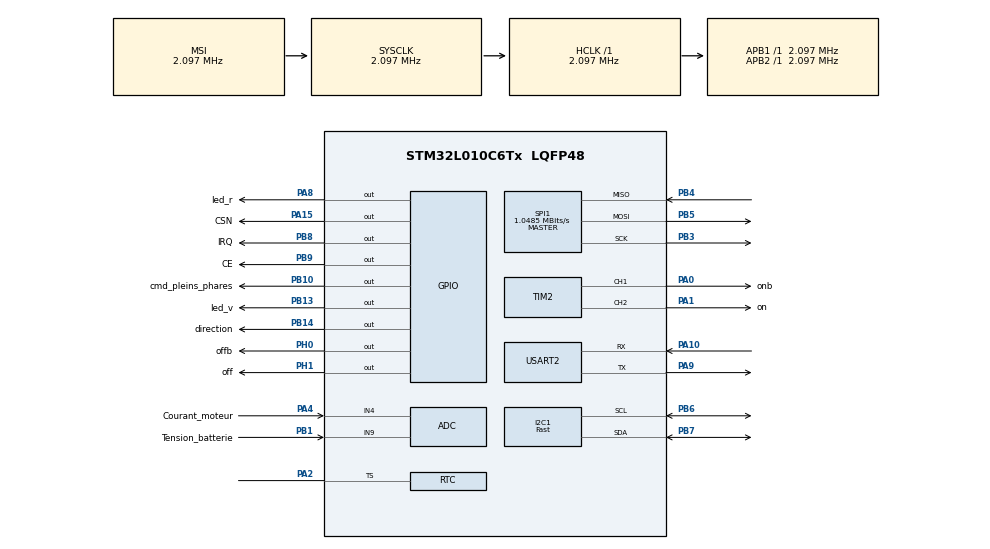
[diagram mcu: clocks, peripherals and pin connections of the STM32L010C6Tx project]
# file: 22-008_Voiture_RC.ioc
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I2C1.I2C_Speed_Mode=I2C_Fast
I2C1.Timing=0x00000000
Mcu.Family=STM32L0
Mcu.Name=STM32L010C6Tx
Mcu.Package=LQFP48
PA0.GPIO_Label=onb
PA0.GPIO_PuPd=GPIO_PULLDOWN
PA0.Signal=S_TIM2_CH1
PA1.GPIO_Label=on
PA1.GPIO_PuPd=GPIO_PULLDOWN
PA1.Signal=S_TIM2_CH2
PA10.Mode=Asynchronous
PA10.Signal=USART2_RX
PA15.GPIO_Label=CSN
PA15.Signal=GPIO_Output
PA2.Mode=Timestamp enabled
PA2.Signal=RTC_TS
PA4.GPIO_Label=Courant_moteur
PA4.Mode=IN4
PA4.Signal=ADC_IN4
PA8.GPIO_Label=led_r
PA8.PinState=GPIO_PIN_SET
PA8.Signal=GPIO_Output
PA9.Mode=Asynchronous
PA9.Signal=USART2_TX
PB1.GPIO_Label=Tension_batterie
PB1.Mode=IN9
PB1.Signal=ADC_IN9
PB10.GPIO_Label=cmd_pleins_phares
PB10.Signal=GPIO_Output
PB13.GPIO_Label=led_v
PB13.PinState=GPIO_PIN_SET
PB13.Signal=GPIO_Output
PB14.GPIO_Label=direction
PB14.Signal=GPIO_Output
PB3.Mode=Full_Duplex_Master
PB3.Signal=SPI1_SCK
PB4.Mode=Full_Duplex_Master
PB4.Signal=SPI1_MISO
PB5.Mode=Full_Duplex_Master
PB5.Signal=SPI1_MOSI
PB6.Mode=I2C
PB6.Signal=I2C1_SCL
PB7.Mode=I2C
PB7.Signal=I2C1_SDA
PB8.GPIO_Label=IRQ
PB8.Signal=GPIO_Output
PB9.GPIO_Label=CE
PB9.Signal=GPIO_Output
PH0-OSC_IN.GPIO_Label=offb
PH0-OSC_IN.GPIO_PuPd=GPIO_PULLDOWN
PH0-OSC_IN.Signal=GPIO_Output
PH1-OSC_OUT.GPIO_Label=off
PH1-OSC_OUT.GPIO_PuPd=GPIO_PULLDOWN
PH1-OSC_OUT.Signal=GPIO_Output
ProjectManager.HeapSize=0x200
ProjectManager.StackSize=0x400
ProjectManager.TargetToolchain=STM32CubeIDE
RCC.AHBFreq_Value=2097000
RCC.APB1Freq_Value=2097000
RCC.APB1TimFreq_Value=2097000
RCC.APB2Freq_Value=2097000
RCC.APB2TimFreq_Value=2097000
RCC.HCLKFreq_Value=2097000
RCC.HSE_VALUE=8000000
RCC.HSI16_VALUE=16000000
RCC.HSI_VALUE=16000000
RCC.LSE_VALUE=32768
RCC.MSI_VALUE=2097000
RCC.SYSCLKFreq_VALUE=2097000
RCC.VCOOutputFreq_Value=48000000
RTC.Year=70
SH.S_TIM2_CH1.0=TIM2_CH1,PWM Generation1 CH1
SH.S_TIM2_CH2.0=TIM2_CH2,PWM Generation2 CH2
SPI1.CalculateBaudRate=1.0485 MBits/s
SPI1.Direction=SPI_DIRECTION_2LINES
SPI1.Mode=SPI_MODE_MASTER
SPI1.VirtualType=VM_MASTER
TIM2.Channel-PWM\ Generation1\ CH1=TIM_CHANNEL_1
TIM2.Channel-PWM\ Generation2\ CH2=TIM_CHANNEL_2
USART2.VirtualMode=VM_ASYNC
VP_RTC_VS_RTC_Activate.Mode=RTC_Enabled
VP_RTC_VS_RTC_Calendar.Mode=RTC_Calendar
VP_TIM2_VS_ClockSourceINT.Mode=Internal
board=custom

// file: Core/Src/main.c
/* USER CODE BEGIN Header */
/**
  ******************************************************************************
  * @file           : main.c
  * @brief          : Main program body
  ******************************************************************************
  * @attention
  *
  * Copyright (c) 2024 STMicroelectronics.
  * All rights reserved.
  *
  * This software is licensed under terms that can be found in the LICENSE file
  * in the root directory of this software component.
  * If no LICENSE file comes with this software, it is provided AS-IS.
  *
  ******************************************************************************
  */
/* USER CODE END Header */
#include "main.h"

/* USER CODE BEGIN Includes */
#include "../Inc/applications.h"
#include "../Inc/hal.h"
/* USER CODE END Includes */

ADC_HandleTypeDef hadc;

I2C_HandleTypeDef hi2c1;

RTC_HandleTypeDef hrtc;

SPI_HandleTypeDef hspi1;

TIM_HandleTypeDef htim2;

UART_HandleTypeDef huart2;

void SystemClock_Config(void);
static void MX_GPIO_Init(void);
static void MX_USART2_UART_Init(void);
static void MX_TIM2_Init(void);
static void MX_ADC_Init(void);
static void MX_SPI1_Init(void);
static void MX_I2C1_Init(void);
static void MX_RTC_Init(void);

int main(void)
{

  /* MCU Configuration--------------------------------------------------------*/

  /* Reset of all peripherals, Initializes the Flash interface and the Systick. */
  HAL_Init();

  /* Configure the system clock */
  SystemClock_Config();

  /* Initialize all configured peripherals */
  MX_GPIO_Init();
  MX_USART2_UART_Init();
  MX_TIM2_Init();
  MX_ADC_Init();
  MX_SPI1_Init();
  MX_I2C1_Init();
  MX_RTC_Init();
  /* USER CODE BEGIN 2 */

  //initialisation du debug
  /* USER CODE END 2 */

  /* Infinite loop */
  while (1)
  {

    /* USER CODE BEGIN 3 */
    //test du debug avec un toggle de la led
    APP_process();
  }
  /* USER CODE END 3 */
}

void SystemClock_Config(void)
{
  RCC_OscInitTypeDef RCC_OscInitStruct = {0};
  RCC_ClkInitTypeDef RCC_ClkInitStruct = {0};
  RCC_PeriphCLKInitTypeDef PeriphClkInit = {0};

  /** Configure the main internal regulator output voltage
  */
  __HAL_PWR_VOLTAGESCALING_CONFIG(PWR_REGULATOR_VOLTAGE_SCALE1);

  /** Initializes the RCC Oscillators according to the specified parameters
  * in the RCC_OscInitTypeDef structure.
  */
  RCC_OscInitStruct.OscillatorType = RCC_OSCILLATORTYPE_LSI|RCC_OSCILLATORTYPE_MSI;
  RCC_OscInitStruct.LSIState = RCC_LSI_ON;
  RCC_OscInitStruct.MSIState = RCC_MSI_ON;
  RCC_OscInitStruct.MSICalibrationValue = 0;
  RCC_OscInitStruct.MSIClockRange = RCC_MSIRANGE_5;
  RCC_OscInitStruct.PLL.PLLState = RCC_PLL_NONE;
  if (HAL_RCC_OscConfig(&RCC_OscInitStruct) != HAL_OK)
  {
    Error_Handler();
  }

  /** Initializes the CPU, AHB and APB buses clocks
  */
  RCC_ClkInitStruct.ClockType = RCC_CLOCKTYPE_HCLK|RCC_CLOCKTYPE_SYSCLK
                              |RCC_CLOCKTYPE_PCLK1|RCC_CLOCKTYPE_PCLK2;
  RCC_ClkInitStruct.SYSCLKSource = RCC_SYSCLKSOURCE_MSI;
  RCC_ClkInitStruct.AHBCLKDivider = RCC_SYSCLK_DIV1;
  RCC_ClkInitStruct.APB1CLKDivider = RCC_HCLK_DIV1;
  RCC_ClkInitStruct.APB2CLKDivider = RCC_HCLK_DIV1;

  if (HAL_RCC_ClockConfig(&RCC_ClkInitStruct, FLASH_LATENCY_0) != HAL_OK)
  {
    Error_Handler();
  }
  PeriphClkInit.PeriphClockSelection = RCC_PERIPHCLK_USART2|RCC_PERIPHCLK_I2C1
                              |RCC_PERIPHCLK_RTC;
  PeriphClkInit.Usart2ClockSelection = RCC_USART2CLKSOURCE_PCLK1;
  PeriphClkInit.I2c1ClockSelection = RCC_I2C1CLKSOURCE_PCLK1;
  PeriphClkInit.RTCClockSelection = RCC_RTCCLKSOURCE_LSI;
  if (HAL_RCCEx_PeriphCLKConfig(&PeriphClkInit) != HAL_OK)
  {
    Error_Handler();
  }
}

static void MX_ADC_Init(void)
{

  ADC_ChannelConfTypeDef sConfig = {0};

  /** Configure the global features of the ADC (Clock, Resolution, Data Alignment and number of conversion)
  */
  hadc.Instance = ADC1;
  hadc.Init.OversamplingMode = DISABLE;
  hadc.Init.ClockPrescaler = ADC_CLOCK_SYNC_PCLK_DIV1;
  hadc.Init.Resolution = ADC_RESOLUTION_12B;
  hadc.Init.SamplingTime = ADC_SAMPLETIME_1CYCLE_5;
  hadc.Init.ScanConvMode = ADC_SCAN_DIRECTION_FORWARD;
  hadc.Init.DataAlign = ADC_DATAALIGN_RIGHT;
  hadc.Init.ContinuousConvMode = DISABLE;
  hadc.Init.DiscontinuousConvMode = DISABLE;
  hadc.Init.ExternalTrigConvEdge = ADC_EXTERNALTRIGCONVEDGE_NONE;
  hadc.Init.ExternalTrigConv = ADC_SOFTWARE_START;
  hadc.Init.DMAContinuousRequests = DISABLE;
  hadc.Init.EOCSelection = ADC_EOC_SINGLE_CONV;
  hadc.Init.Overrun = ADC_OVR_DATA_PRESERVED;
  hadc.Init.LowPowerAutoWait = DISABLE;
  hadc.Init.LowPowerFrequencyMode = ENABLE;
  hadc.Init.LowPowerAutoPowerOff = DISABLE;
  if (HAL_ADC_Init(&hadc) != HAL_OK)
  {
    Error_Handler();
  }

  /** Configure for the selected ADC regular channel to be converted.
  */
  sConfig.Channel = ADC_CHANNEL_4;
  sConfig.Rank = ADC_RANK_CHANNEL_NUMBER;
  if (HAL_ADC_ConfigChannel(&hadc, &sConfig) != HAL_OK)
  {
    Error_Handler();
  }

  /** Configure for the selected ADC regular channel to be converted.
  */
  sConfig.Channel = ADC_CHANNEL_9;
  if (HAL_ADC_ConfigChannel(&hadc, &sConfig) != HAL_OK)
  {
    Error_Handler();
  }

}

static void MX_I2C1_Init(void)
{

  hi2c1.Instance = I2C1;
  hi2c1.Init.Timing = 0x00000000;
  hi2c1.Init.OwnAddress1 = 0;
  hi2c1.Init.AddressingMode = I2C_ADDRESSINGMODE_7BIT;
  hi2c1.Init.DualAddressMode = I2C_DUALADDRESS_DISABLE;
  hi2c1.Init.OwnAddress2 = 0;
  hi2c1.Init.OwnAddress2Masks = I2C_OA2_NOMASK;
  hi2c1.Init.GeneralCallMode = I2C_GENERALCALL_DISABLE;
  hi2c1.Init.NoStretchMode = I2C_NOSTRETCH_DISABLE;
  if (HAL_I2C_Init(&hi2c1) != HAL_OK)
  {
    Error_Handler();
  }

  /** Configure Analogue filter
  */
  if (HAL_I2CEx_ConfigAnalogFilter(&hi2c1, I2C_ANALOGFILTER_ENABLE) != HAL_OK)
  {
    Error_Handler();
  }

  /** Configure Digital filter
  */
  if (HAL_I2CEx_ConfigDigitalFilter(&hi2c1, 0) != HAL_OK)
  {
    Error_Handler();
  }

}

static void MX_RTC_Init(void)
{

  RTC_TimeTypeDef sTime = {0};
  RTC_DateTypeDef sDate = {0};

  /** Initialize RTC Only
  */
  hrtc.Instance = RTC;
  hrtc.Init.HourFormat = RTC_HOURFORMAT_24;
  hrtc.Init.AsynchPrediv = 127;
  hrtc.Init.SynchPrediv = 255;
  hrtc.Init.OutPut = RTC_OUTPUT_DISABLE;
  hrtc.Init.OutPutRemap = RTC_OUTPUT_REMAP_NONE;
  hrtc.Init.OutPutPolarity = RTC_OUTPUT_POLARITY_HIGH;
  hrtc.Init.OutPutType = RTC_OUTPUT_TYPE_OPENDRAIN;
  if (HAL_RTC_Init(&hrtc) != HAL_OK)
  {
    Error_Handler();
  }

  /** Initialize RTC and set the Time and Date
  */
  sTime.Hours = 0x0;
  sTime.Minutes = 0x0;
  sTime.Seconds = 0x0;
  sTime.DayLightSaving = RTC_DAYLIGHTSAVING_NONE;
  sTime.StoreOperation = RTC_STOREOPERATION_RESET;
  if (HAL_RTC_SetTime(&hrtc, &sTime, RTC_FORMAT_BCD) != HAL_OK)
  {
    Error_Handler();
  }
  sDate.WeekDay = RTC_WEEKDAY_MONDAY;
  sDate.Month = RTC_MONTH_JANUARY;
  sDate.Date = 0x1;
  sDate.Year = 0x70;

  if (HAL_RTC_SetDate(&hrtc, &sDate, RTC_FORMAT_BCD) != HAL_OK)
  {
    Error_Handler();
  }

  /** Enable the TimeStamp
  */
  if (HAL_RTCEx_SetTimeStamp(&hrtc, RTC_TIMESTAMPEDGE_RISING, RTC_TIMESTAMPPIN_DEFAULT) != HAL_OK)
  {
    Error_Handler();
  }

}

static void MX_SPI1_Init(void)
{

  /* SPI1 parameter configuration*/
  hspi1.Instance = SPI1;
  hspi1.Init.Mode = SPI_MODE_MASTER;
  hspi1.Init.Direction = SPI_DIRECTION_2LINES;
  hspi1.Init.DataSize = SPI_DATASIZE_8BIT;
  hspi1.Init.CLKPolarity = SPI_POLARITY_LOW;
  hspi1.Init.CLKPhase = SPI_PHASE_1EDGE;
  hspi1.Init.NSS = SPI_NSS_SOFT;
  hspi1.Init.BaudRatePrescaler = SPI_BAUDRATEPRESCALER_2;
  hspi1.Init.FirstBit = SPI_FIRSTBIT_MSB;
  hspi1.Init.TIMode = SPI_TIMODE_DISABLE;
  hspi1.Init.CRCCalculation = SPI_CRCCALCULATION_DISABLE;
  hspi1.Init.CRCPolynomial = 7;
  if (HAL_SPI_Init(&hspi1) != HAL_OK)
  {
    Error_Handler();
  }

}

static void MX_TIM2_Init(void)
{

  TIM_ClockConfigTypeDef sClockSourceConfig = {0};
  TIM_MasterConfigTypeDef sMasterConfig = {0};
  TIM_OC_InitTypeDef sConfigOC = {0};

  htim2.Instance = TIM2;
  htim2.Init.Prescaler = 0;
  htim2.Init.CounterMode = TIM_COUNTERMODE_UP;
  htim2.Init.Period = 65535;
  htim2.Init.ClockDivision = TIM_CLOCKDIVISION_DIV1;
  htim2.Init.AutoReloadPreload = TIM_AUTORELOAD_PRELOAD_DISABLE;
  if (HAL_TIM_Base_Init(&htim2) != HAL_OK)
  {
    Error_Handler();
  }
  sClockSourceConfig.ClockSource = TIM_CLOCKSOURCE_INTERNAL;
  if (HAL_TIM_ConfigClockSource(&htim2, &sClockSourceConfig) != HAL_OK)
  {
    Error_Handler();
  }
  if (HAL_TIM_PWM_Init(&htim2) != HAL_OK)
  {
    Error_Handler();
  }
  sMasterConfig.MasterOutputTrigger = TIM_TRGO_RESET;
  sMasterConfig.MasterSlaveMode = TIM_MASTERSLAVEMODE_DISABLE;
  if (HAL_TIMEx_MasterConfigSynchronization(&htim2, &sMasterConfig) != HAL_OK)
  {
    Error_Handler();
  }
  sConfigOC.OCMode = TIM_OCMODE_PWM1;
  sConfigOC.Pulse = 0;
  sConfigOC.OCPolarity = TIM_OCPOLARITY_HIGH;
  sConfigOC.OCFastMode = TIM_OCFAST_DISABLE;
  if (HAL_TIM_PWM_ConfigChannel(&htim2, &sConfigOC, TIM_CHANNEL_1) != HAL_OK)
  {
    Error_Handler();
  }
  if (HAL_TIM_PWM_ConfigChannel(&htim2, &sConfigOC, TIM_CHANNEL_2) != HAL_OK)
  {
    Error_Handler();
  }
  HAL_TIM_MspPostInit(&htim2);

}

static void MX_USART2_UART_Init(void)
{

  huart2.Instance = USART2;
  huart2.Init.BaudRate = 115200;
  huart2.Init.WordLength = UART_WORDLENGTH_8B;
  huart2.Init.StopBits = UART_STOPBITS_1;
  huart2.Init.Parity = UART_PARITY_NONE;
  huart2.Init.Mode = UART_MODE_TX_RX;
  huart2.Init.HwFlowCtl = UART_HWCONTROL_NONE;
  huart2.Init.OverSampling = UART_OVERSAMPLING_16;
  huart2.Init.OneBitSampling = UART_ONE_BIT_SAMPLE_DISABLE;
  huart2.AdvancedInit.AdvFeatureInit = UART_ADVFEATURE_NO_INIT;
  if (HAL_UART_Init(&huart2) != HAL_OK)
  {
    Error_Handler();
  }

}

static void MX_GPIO_Init(void)
{
  GPIO_InitTypeDef GPIO_InitStruct = {0};

  /* GPIO Ports Clock Enable */
  __HAL_RCC_GPIOH_CLK_ENABLE();
  __HAL_RCC_GPIOA_CLK_ENABLE();
  __HAL_RCC_GPIOB_CLK_ENABLE();

  /*Configure GPIO pin Output Level */
  HAL_GPIO_WritePin(GPIOH, offb_Pin|off_Pin, GPIO_PIN_RESET);

  /*Configure GPIO pin Output Level */
  HAL_GPIO_WritePin(GPIOB, cmd_pleins_phares_Pin|direction_Pin|IRQ_Pin|CE_Pin, GPIO_PIN_RESET);

  /*Configure GPIO pin Output Level */
  HAL_GPIO_WritePin(led_v_GPIO_Port, led_v_Pin, GPIO_PIN_SET);

  /*Configure GPIO pin Output Level */
  HAL_GPIO_WritePin(led_r_GPIO_Port, led_r_Pin, GPIO_PIN_SET);

  /*Configure GPIO pin Output Level */
  HAL_GPIO_WritePin(CSN_GPIO_Port, CSN_Pin, GPIO_PIN_RESET);

  /*Configure GPIO pins : offb_Pin off_Pin */
  GPIO_InitStruct.Pin = offb_Pin|off_Pin;
  GPIO_InitStruct.Mode = GPIO_MODE_OUTPUT_PP;
  GPIO_InitStruct.Pull = GPIO_PULLDOWN;
  GPIO_InitStruct.Speed = GPIO_SPEED_FREQ_LOW;
  HAL_GPIO_Init(GPIOH, &GPIO_InitStruct);

  /*Configure GPIO pins : cmd_pleins_phares_Pin led_v_Pin direction_Pin IRQ_Pin
                           CE_Pin */
  GPIO_InitStruct.Pin = cmd_pleins_phares_Pin|led_v_Pin|direction_Pin|IRQ_Pin
                          |CE_Pin;
  GPIO_InitStruct.Mode = GPIO_MODE_OUTPUT_PP;
  GPIO_InitStruct.Pull = GPIO_NOPULL;
  GPIO_InitStruct.Speed = GPIO_SPEED_FREQ_LOW;
  HAL_GPIO_Init(GPIOB, &GPIO_InitStruct);

  /*Configure GPIO pins : led_r_Pin CSN_Pin */
  GPIO_InitStruct.Pin = led_r_Pin|CSN_Pin;
  GPIO_InitStruct.Mode = GPIO_MODE_OUTPUT_PP;
  GPIO_InitStruct.Pull = GPIO_NOPULL;
  GPIO_InitStruct.Speed = GPIO_SPEED_FREQ_LOW;
  HAL_GPIO_Init(GPIOA, &GPIO_InitStruct);

}

void Error_Handler(void)
{
  __disable_irq();
  while (1)
  {
  }
}
